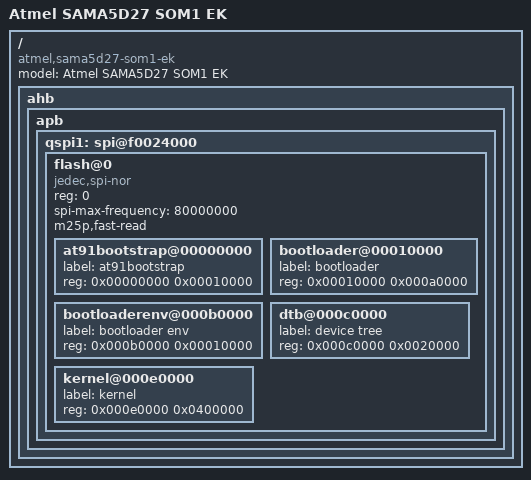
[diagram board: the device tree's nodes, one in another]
/*
 * at91-sama5d27_som1_ek.dts - Device Tree file for SAMA5D27-SOM1-EK board
 *
 *  Copyright (c) 2017, Microchip Technology Inc.
 *                2016 Nicolas Ferre <nicolas.ferre@atmel.com>
 *                2017 Cristian Birsan <cristian.birsan@microchip.com>
 *                2017 Claudiu Beznea <claudiu.beznea@microchip.com>
 *
 * This file is dual-licensed: you can use it either under the terms
 * of the GPL or the X11 license, at your option. Note that this dual
 * licensing only applies to this file, and not this project as a
 * whole.
 *
 *  a) This file is free software; you can redistribute it and/or
 *     modify it under the terms of the GNU General Public License as
 *     published by the Free Software Foundation; either version 2 of the
 *     License, or (at your option) any later version.
 *
 *     This file is distributed in the hope that it will be useful,
 *     but WITHOUT ANY WARRANTY; without even the implied warranty of
 *     MERCHANTABILITY or FITNESS FOR A PARTICULAR PURPOSE.  See the
 *     GNU General Public License for more details.
 *
 * Or, alternatively,
 *
 *  b) Permission is hereby granted, free of charge, to any person
 *     obtaining a copy of this software and associated documentation
 *     files (the "Software"), to deal in the Software without
 *     restriction, including without limitation the rights to use,
 *     copy, modify, merge, publish, distribute, sublicense, and/or
 *     sell copies of the Software, and to permit persons to whom the
 *     Software is furnished to do so, subject to the following
 *     conditions:
 *
 *     The above copyright notice and this permission notice shall be
 *     included in all copies or substantial portions of the Software.
 *
 *     THE SOFTWARE IS PROVIDED "AS IS", WITHOUT WARRANTY OF ANY KIND,
 *     EXPRESS OR IMPLIED, INCLUDING BUT NOT LIMITED TO THE WARRANTIES
 *     OF MERCHANTABILITY, FITNESS FOR A PARTICULAR PURPOSE AND
 *     NONINFRINGEMENT. IN NO EVENT SHALL THE AUTHORS OR COPYRIGHT
 *     HOLDERS BE LIABLE FOR ANY CLAIM, DAMAGES OR OTHER LIABILITY,
 *     WHETHER IN AN ACTION OF CONTRACT, TORT OR OTHERWISE, ARISING
 *     FROM, OUT OF OR IN CONNECTION WITH THE SOFTWARE OR THE USE OR
 *     OTHER DEALINGS IN THE SOFTWARE.
 */
/dts-v1/;
#include "at91-sama5d27_som1_ek_common.dtsi"

/ {
	model = "Atmel SAMA5D27 SOM1 EK";
	compatible = "atmel,sama5d27-som1-ek", "atmel,sama5d27-som1", "atmel,sama5d27", "atmel,sama5d2", "atmel,sama5";

	ahb {
		apb {
			qspi1: spi@f0024000 {
				flash@0 {
					#address-cells = <1>;
					#size-cells = <1>;
					compatible = "jedec,spi-nor";
					reg = <0>;
					spi-max-frequency = <80000000>;
					m25p,fast-read;

					at91bootstrap@00000000 {
						label = "at91bootstrap";
						reg = <0x00000000 0x00010000>;
					};

					bootloader@00010000 {
						label = "bootloader";
						reg = <0x00010000 0x000a0000>;
					};

					bootloaderenv@000b0000 {
						label = "bootloader env";
						reg = <0x000b0000 0x00010000>;
					};

					dtb@000c0000 {
						label = "device tree";
						reg = <0x000c0000 0x0020000>;
					};

					kernel@000e0000 {
						label = "kernel";
						reg = <0x000e0000 0x0400000>;
					};
				};
			};
		};
	};
};
